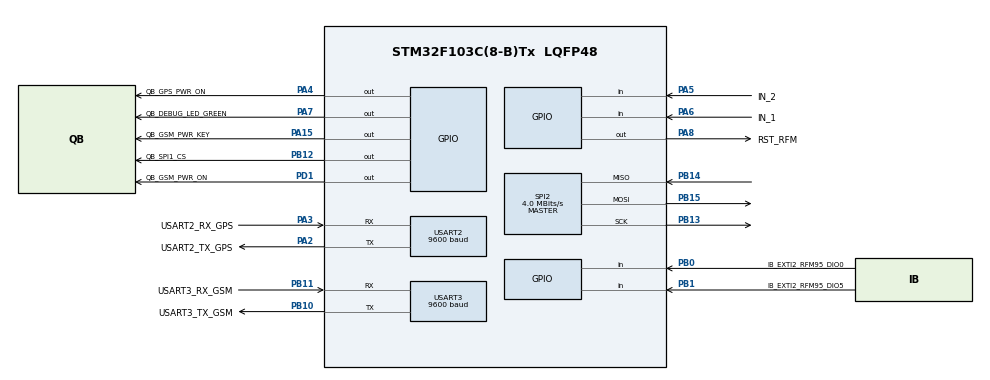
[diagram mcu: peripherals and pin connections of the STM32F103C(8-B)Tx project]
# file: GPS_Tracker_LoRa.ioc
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Dma.Request0=USART2_RX
Dma.Request1=USART3_RX
Dma.USART2_RX.0.Direction=DMA_PERIPH_TO_MEMORY
Dma.USART2_RX.0.Instance=DMA1_Channel6
Dma.USART2_RX.0.MemDataAlignment=DMA_MDATAALIGN_BYTE
Dma.USART2_RX.0.MemInc=DMA_MINC_ENABLE
Dma.USART2_RX.0.Mode=DMA_CIRCULAR
Dma.USART2_RX.0.PeriphDataAlignment=DMA_PDATAALIGN_BYTE
Dma.USART2_RX.0.PeriphInc=DMA_PINC_DISABLE
Dma.USART2_RX.0.Priority=DMA_PRIORITY_LOW
Dma.USART3_RX.1.Direction=DMA_PERIPH_TO_MEMORY
Dma.USART3_RX.1.Instance=DMA1_Channel3
Dma.USART3_RX.1.MemDataAlignment=DMA_MDATAALIGN_BYTE
Dma.USART3_RX.1.MemInc=DMA_MINC_ENABLE
Dma.USART3_RX.1.Mode=DMA_CIRCULAR
Dma.USART3_RX.1.PeriphDataAlignment=DMA_PDATAALIGN_BYTE
Dma.USART3_RX.1.PeriphInc=DMA_PINC_DISABLE
Dma.USART3_RX.1.Priority=DMA_PRIORITY_LOW
Mcu.Family=STM32F1
Mcu.Name=STM32F103C(8-B)Tx
Mcu.Package=LQFP48
NVIC.DMA1_Channel3_IRQn=true\:0\:0\:false\:false\:true\:false
NVIC.DMA1_Channel6_IRQn=true\:0\:0\:false\:false\:true\:false
NVIC.PriorityGroup=NVIC_PRIORITYGROUP_4
NVIC.RTC_Alarm_IRQn=true\:0\:0\:false\:false\:true\:true
NVIC.USART2_IRQn=true\:0\:0\:false\:false\:true\:true
NVIC.USART3_IRQn=true\:0\:0\:false\:false\:true\:true
PA13.Mode=Serial_Wire
PA13.Signal=SYS_JTMS-SWDIO
PA14.Mode=Serial_Wire
PA14.Signal=SYS_JTCK-SWCLK
PA15.GPIO_Label=QB_GSM_PWR_KEY
PA15.Signal=GPIO_Output
PA2.GPIO_Label=USART2_TX_GPS
PA2.GPIO_Speed=GPIO_SPEED_FREQ_HIGH
PA2.Mode=Asynchronous
PA2.Signal=USART2_TX
PA3.GPIO_Label=USART2_RX_GPS
PA3.Mode=Asynchronous
PA3.Signal=USART2_RX
PA4.GPIO_Label=QB_GPS_PWR_ON
PA4.Signal=GPIO_Output
PA5.GPIO_Label=IN_2
PA5.GPIO_PuPd=GPIO_PULLDOWN
PA5.Signal=GPIO_Input
PA6.GPIO_Label=IN_1
PA6.GPIO_PuPd=GPIO_PULLDOWN
PA6.Signal=GPIO_Input
PA7.GPIO_Label=QB_DEBUG_LED_GREEN
PA7.Signal=GPIO_Output
PA8.GPIO_Label=RST_RFM
PA8.Signal=GPIO_Output
PB0.GPIO_Label=IB_EXTI2_RFM95_DIO0
PB0.Signal=GPIO_Input
PB1.GPIO_Label=IB_EXTI2_RFM95_DIO5
PB1.Signal=GPIO_Input
PB10.GPIO_Label=USART3_TX_GSM
PB10.Mode=Asynchronous
PB10.Signal=USART3_TX
PB11.GPIO_Label=USART3_RX_GSM
PB11.Mode=Asynchronous
PB11.Signal=USART3_RX
PB12.GPIO_Label=QB_SPI1_CS
PB12.Signal=GPIO_Output
PB13.Mode=Full_Duplex_Master
PB13.Signal=SPI2_SCK
PB14.Mode=Full_Duplex_Master
PB14.Signal=SPI2_MISO
PB15.Mode=Full_Duplex_Master
PB15.Signal=SPI2_MOSI
PD1-OSC_OUT.GPIO_Label=QB_GSM_PWR_ON
PD1-OSC_OUT.Signal=GPIO_Output
ProjectManager.HeapSize=0x200
ProjectManager.StackSize=0x400
ProjectManager.TargetToolchain=SW4STM32
RCC.APB1Freq_Value=8000000
RCC.APB2Freq_Value=8000000
SPI2.CalculateBaudRate=4.0 MBits/s
SPI2.Direction=SPI_DIRECTION_2LINES
SPI2.Mode=SPI_MODE_MASTER
SPI2.VirtualType=VM_MASTER
USART2.BaudRate=9600
USART2.VirtualMode=VM_ASYNC
USART3.BaudRate=9600
USART3.VirtualMode=VM_ASYNC
VP_RTC_No_RTC_Output.Mode=RTC_OUT_NO
VP_RTC_VS_RTC_Activate.Mode=RTC_Enabled
VP_RTC_VS_RTC_Calendar.Mode=RTC_Calendar
board=custom

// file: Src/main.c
/**
  ******************************************************************************
  * @file           : main.c
  * @brief          : Main program body
  ******************************************************************************
  ** This notice applies to any and all portions of this file
  * that are not between comment pairs USER CODE BEGIN and
  * USER CODE END. Other portions of this file, whether
  * inserted by the user or by software development tools
  * are owned by their respective copyright owners.
  *
  * COPYRIGHT(c) 2018 STMicroelectronics
  *
  * Redistribution and use in source and binary forms, with or without modification,
  * are permitted provided that the following conditions are met:
  *   1. Redistributions of source code must retain the above copyright notice,
  *      this list of conditions and the following disclaimer.
  *   2. Redistributions in binary form must reproduce the above copyright notice,
  *      this list of conditions and the following disclaimer in the documentation
  *      and/or other materials provided with the distribution.
  *   3. Neither the name of STMicroelectronics nor the names of its contributors
  *      may be used to endorse or promote products derived from this software
  *      without specific prior written permission.
  *
  * THIS SOFTWARE IS PROVIDED BY THE COPYRIGHT HOLDERS AND CONTRIBUTORS "AS IS"
  * AND ANY EXPRESS OR IMPLIED WARRANTIES, INCLUDING, BUT NOT LIMITED TO, THE
  * IMPLIED WARRANTIES OF MERCHANTABILITY AND FITNESS FOR A PARTICULAR PURPOSE ARE
  * DISCLAIMED. IN NO EVENT SHALL THE COPYRIGHT HOLDER OR CONTRIBUTORS BE LIABLE
  * FOR ANY DIRECT, INDIRECT, INCIDENTAL, SPECIAL, EXEMPLARY, OR CONSEQUENTIAL
  * DAMAGES (INCLUDING, BUT NOT LIMITED TO, PROCUREMENT OF SUBSTITUTE GOODS OR
  * SERVICES; LOSS OF USE, DATA, OR PROFITS; OR BUSINESS INTERRUPTION) HOWEVER
  * CAUSED AND ON ANY THEORY OF LIABILITY, WHETHER IN CONTRACT, STRICT LIABILITY,
  * OR TORT (INCLUDING NEGLIGENCE OR OTHERWISE) ARISING IN ANY WAY OUT OF THE USE
  * OF THIS SOFTWARE, EVEN IF ADVISED OF THE POSSIBILITY OF SUCH DAMAGE.
  *
  ******************************************************************************
  */
#include "main.h"
#include "stm32f1xx_hal.h"
#include "dma.h"
#include "rtc.h"
#include "spi.h"
#include "usart.h"
#include "gpio.h"
#include "sim_config.h"
/* USER CODE BEGIN Includes */
#include "common_fun.h"
/* USER CODE END Includes */

/* USER CODE BEGIN PV */
/* Private variables ---------------------------------------------------------*/

/* USER CODE END PV */

void SystemClock_Config(void);

/* USER CODE BEGIN PFP */
/* Private function prototypes -----------------------------------------------*/
/* USER CODE END PFP */

int main(void)
{

  /* MCU Configuration----------------------------------------------------------*/

  /* Reset of all peripherals, Initializes the Flash interface and the Systick. */
 HAL_Init();

  /* Configure the system clock */
  SystemClock_Config();

  /* Initialize all configured peripherals */
  MX_GPIO_Init();
  MX_DMA_Init();
  MX_USART2_UART_Init();
  MX_USART3_UART_Init();
  MX_SPI2_Init();
  MX_RTC_Init();
  /* USER CODE BEGIN 2 */
  GPS_GSM_Tracker_init();
  /* USER CODE END 2 */

  /* Infinite loop */
  /* USER CODE BEGIN WHILE */
#ifdef ONLY_LORA
  LoRa_Panic();
#endif

  while (1)
  {
      if (RTC_WakeUp())
      {
          while (GPS_GSM_TrackerTask()) {};
      }
     RTC_GoSleep();
  }
  /* USER CODE END 3 */

}

void SystemClock_Config(void)
{

  RCC_OscInitTypeDef RCC_OscInitStruct;
  RCC_ClkInitTypeDef RCC_ClkInitStruct;
  RCC_PeriphCLKInitTypeDef PeriphClkInit;

    /**Initializes the CPU, AHB and APB busses clocks
    */
  RCC_OscInitStruct.OscillatorType = RCC_OSCILLATORTYPE_HSI|RCC_OSCILLATORTYPE_LSI;
  RCC_OscInitStruct.HSIState = RCC_HSI_ON;
  RCC_OscInitStruct.HSICalibrationValue = 16;
  RCC_OscInitStruct.LSIState = RCC_LSI_ON;
  RCC_OscInitStruct.PLL.PLLState = RCC_PLL_NONE;
  if (HAL_RCC_OscConfig(&RCC_OscInitStruct) != HAL_OK)
  {
    _Error_Handler(__FILE__, __LINE__);
  }

    /**Initializes the CPU, AHB and APB busses clocks
    */
  RCC_ClkInitStruct.ClockType = RCC_CLOCKTYPE_HCLK|RCC_CLOCKTYPE_SYSCLK
                              |RCC_CLOCKTYPE_PCLK1|RCC_CLOCKTYPE_PCLK2;
  RCC_ClkInitStruct.SYSCLKSource = RCC_SYSCLKSOURCE_HSI;
  RCC_ClkInitStruct.AHBCLKDivider = RCC_SYSCLK_DIV1;
  RCC_ClkInitStruct.APB1CLKDivider = RCC_HCLK_DIV1;
  RCC_ClkInitStruct.APB2CLKDivider = RCC_HCLK_DIV1;

  if (HAL_RCC_ClockConfig(&RCC_ClkInitStruct, FLASH_LATENCY_0) != HAL_OK)
  {
    _Error_Handler(__FILE__, __LINE__);
  }

  PeriphClkInit.PeriphClockSelection = RCC_PERIPHCLK_RTC;
  PeriphClkInit.RTCClockSelection = RCC_RTCCLKSOURCE_LSI;
  if (HAL_RCCEx_PeriphCLKConfig(&PeriphClkInit) != HAL_OK)
  {
    _Error_Handler(__FILE__, __LINE__);
  }

    /**Configure the Systick interrupt time
    */
  HAL_SYSTICK_Config(HAL_RCC_GetHCLKFreq()/1000);

    /**Configure the Systick
    */
  HAL_SYSTICK_CLKSourceConfig(SYSTICK_CLKSOURCE_HCLK);

  /* SysTick_IRQn interrupt configuration */
  HAL_NVIC_SetPriority(SysTick_IRQn, 0, 0);
}

/* USER CODE END 4 */

void _Error_Handler(char *file, int line)
{
  while(1)
  {
  }
}

/************************ (C) COPYRIGHT STMicroelectronics *****END OF FILE****/
